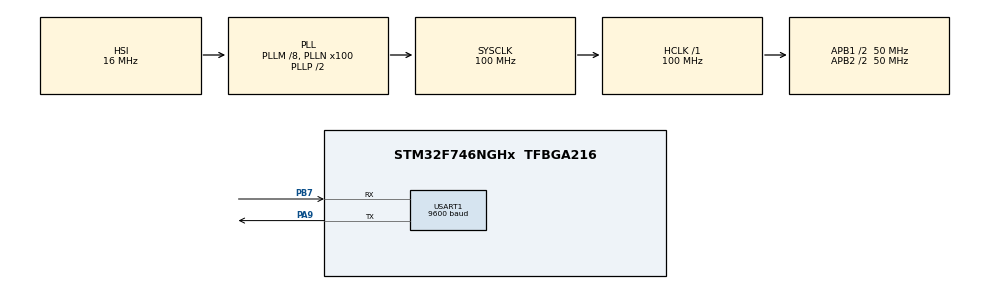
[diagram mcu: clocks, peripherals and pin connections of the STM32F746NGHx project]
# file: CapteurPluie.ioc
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Mcu.Family=STM32F7
Mcu.Name=STM32F746NGHx
Mcu.Package=TFBGA216
NVIC.PriorityGroup=NVIC_PRIORITYGROUP_4
NVIC.TIM6_DAC_IRQn=true\:0\:0\:false\:false\:true\:true\:true\:true
PA13.Mode=Serial_Wire
PA13.Signal=SYS_JTMS-SWDIO
PA14.Mode=Serial_Wire
PA14.Signal=SYS_JTCK-SWCLK
PA9.Mode=Asynchronous
PA9.Signal=USART1_TX
PB7.Mode=Asynchronous
PB7.Signal=USART1_RX
PH0/OSC_IN.Mode=HSE-External-Oscillator
PH0/OSC_IN.Signal=RCC_OSC_IN
PH1/OSC_OUT.Mode=HSE-External-Oscillator
PH1/OSC_OUT.Signal=RCC_OSC_OUT
ProjectManager.HeapSize=0x200
ProjectManager.StackSize=0x400
ProjectManager.TargetToolchain=STM32CubeIDE
RCC.AHBFreq_Value=100000000
RCC.APB1CLKDivider=RCC_HCLK_DIV2
RCC.APB1Freq_Value=50000000
RCC.APB1TimFreq_Value=100000000
RCC.APB2CLKDivider=RCC_HCLK_DIV2
RCC.APB2Freq_Value=50000000
RCC.APB2TimFreq_Value=100000000
RCC.CortexFreq_Value=100000000
RCC.HCLKFreq_Value=100000000
RCC.HSE_VALUE=25000000
RCC.HSI_VALUE=16000000
RCC.LSE_VALUE=32768
RCC.PLLM=8
RCC.PLLN=100
RCC.PLLSourceVirtual=RCC_PLLSOURCE_HSI
RCC.SYSCLKFreq_VALUE=100000000
RCC.SYSCLKSource=RCC_SYSCLKSOURCE_PLLCLK
RCC.USBFreq_Value=100000000
RCC.VCOOutputFreq_Value=200000000
USART1.BaudRate=9600
USART1.VirtualMode-Asynchronous=VM_ASYNC
VP_TIM6_VS_ClockSourceINT.Mode=Enable_Timer
board=STM32F746G-DISCO

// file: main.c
/* USER CODE BEGIN Header */
/**
  ******************************************************************************
  * @file           : main.c
  * @brief          : Main program body
  ******************************************************************************
  * @attention
  *
  * Copyright (c) 2022 STMicroelectronics.
  * All rights reserved.
  *
  * This software is licensed under terms that can be found in the LICENSE file
  * in the root directory of this software component.
  * If no LICENSE file comes with this software, it is provided AS-IS.
  *
  ******************************************************************************
  */
/* USER CODE END Header */
#include "main.h"
#include "tim.h"
#include "usart.h"
#include "gpio.h"

/* USER CODE BEGIN Includes */
#include<stdio.h>
#include<string.h>
#ifdef __GNUC__

/* With GCC/RAISONANCE, small printf (option LD Linker->Librairies->Small printf
 * set to 'Yes') calls __io_putchar() */
#define PUTCHAR_PROTOTYPE int __io_putchar(int ch)
#else
#define PUTCHAR_PROTOTYPE int fputc(int ch, FILE *f)
#endif /* __GNUC__*/
/* USER CODE END Includes */

/* USER CODE BEGIN PV */
extern UART_HandleTypeDef huart1;
char Flag_Pluie;
uint8_t Bucket;
uint8_t ValeurPluie;
/* USER CODE END PV */

void SystemClock_Config(void);

int main(void)
{

  /* MCU Configuration--------------------------------------------------------*/

  /* Reset of all peripherals, Initializes the Flash interface and the Systick. */
  HAL_Init();

  /* Configure the system clock */
  SystemClock_Config();

  /* Initialize all configured peripherals */
  MX_GPIO_Init();
  MX_TIM6_Init();
  MX_USART1_UART_Init();
  /* USER CODE BEGIN 2 */
  HAL_TIM_Base_Start_IT(&htim6);
  uint8_t ValeurPluie=0;
  uint8_t Bucket=3;
  /* USER CODE END 2 */

  /* Infinite loop */
  /* USER CODE BEGIN WHILE */
  while (1)
  {
	  Rain();
	  /*if (Flag_Pluie==1)
	  {
		  printf("Quantite de pluie:\r\n",ValeurPluie);
		  ValeurPluie+=Bucket;
		  Flag_Pluie=0;
	  }
	  else
	  {
		  HAL_SuspendTick();
		  HAL_PWR_EnterSLEEPMode(PWR_MAINREGULATOR_ON, PWR_SLEEPENTRY_WFE);
	  }*/
    /* USER CODE END WHILE */

  }
}

void SystemClock_Config(void)
{
  RCC_OscInitTypeDef RCC_OscInitStruct = {0};
  RCC_ClkInitTypeDef RCC_ClkInitStruct = {0};

  /** Configure the main internal regulator output voltage
  */
  __HAL_RCC_PWR_CLK_ENABLE();
  __HAL_PWR_VOLTAGESCALING_CONFIG(PWR_REGULATOR_VOLTAGE_SCALE3);

  /** Initializes the RCC Oscillators according to the specified parameters
  * in the RCC_OscInitTypeDef structure.
  */
  RCC_OscInitStruct.OscillatorType = RCC_OSCILLATORTYPE_HSI;
  RCC_OscInitStruct.HSIState = RCC_HSI_ON;
  RCC_OscInitStruct.HSICalibrationValue = RCC_HSICALIBRATION_DEFAULT;
  RCC_OscInitStruct.PLL.PLLState = RCC_PLL_ON;
  RCC_OscInitStruct.PLL.PLLSource = RCC_PLLSOURCE_HSI;
  RCC_OscInitStruct.PLL.PLLM = 8;
  RCC_OscInitStruct.PLL.PLLN = 100;
  RCC_OscInitStruct.PLL.PLLP = RCC_PLLP_DIV2;
  RCC_OscInitStruct.PLL.PLLQ = 2;
  if (HAL_RCC_OscConfig(&RCC_OscInitStruct) != HAL_OK)
  {
    Error_Handler();
  }

  /** Activate the Over-Drive mode
  */
  if (HAL_PWREx_EnableOverDrive() != HAL_OK)
  {
    Error_Handler();
  }

  /** Initializes the CPU, AHB and APB buses clocks
  */
  RCC_ClkInitStruct.ClockType = RCC_CLOCKTYPE_HCLK|RCC_CLOCKTYPE_SYSCLK
                              |RCC_CLOCKTYPE_PCLK1|RCC_CLOCKTYPE_PCLK2;
  RCC_ClkInitStruct.SYSCLKSource = RCC_SYSCLKSOURCE_PLLCLK;
  RCC_ClkInitStruct.AHBCLKDivider = RCC_SYSCLK_DIV1;
  RCC_ClkInitStruct.APB1CLKDivider = RCC_HCLK_DIV2;
  RCC_ClkInitStruct.APB2CLKDivider = RCC_HCLK_DIV2;

  if (HAL_RCC_ClockConfig(&RCC_ClkInitStruct, FLASH_LATENCY_3) != HAL_OK)
  {
    Error_Handler();
  }
}

/* USER CODE BEGIN 4 */
void Rain(void)
{
	if (Flag_Pluie==1)
		{
			printf("Pluie: %d\r\n", ValeurPluie);
			ValeurPluie+=3;
			Flag_Pluie=0;
		}
	else
	{
		HAL_PWR_EnterSLEEPMode(PWR_MAINREGULATOR_ON, PWR_SLEEPENTRY_WFE);
		HAL_SuspendTick();
	}
}
PUTCHAR_PROTOTYPE
{
/*Place your implementation of fputc here*/
/*e.g. write a character to the USART1 and Loop until the end of transmission*/
	HAL_UART_Transmit(&huart1,(uint8_t *)&ch, 1, 100);
	return ch;
}
/* USER CODE END 4 */

void Error_Handler(void)
{
  __disable_irq();
  while (1)
  {
  }
}
